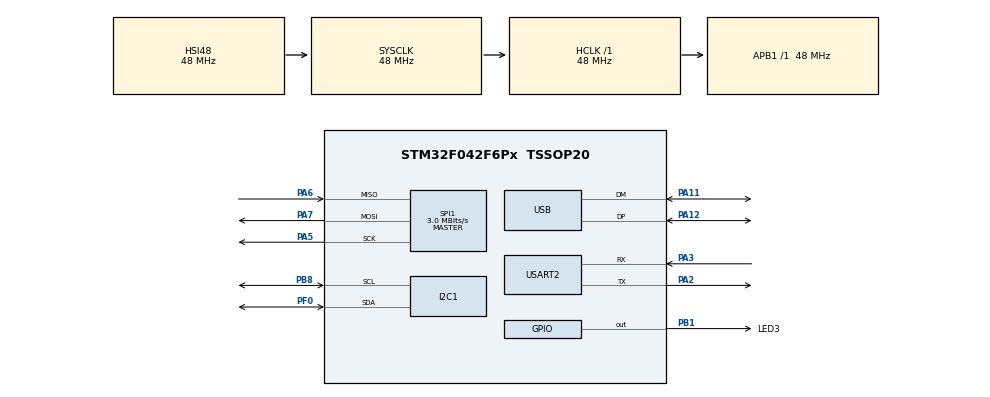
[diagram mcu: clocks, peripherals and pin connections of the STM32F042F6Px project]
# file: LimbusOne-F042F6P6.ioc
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Mcu.Family=STM32F0
Mcu.Name=STM32F042F6Px
Mcu.Package=TSSOP20
NVIC.USB_IRQn=true\:0\:0\:false\:false\:true\:false\:true\:true
PA11.Mode=Device
PA11.Signal=USB_DM
PA12.Mode=Device
PA12.Signal=USB_DP
PA13.Mode=Serial_Wire
PA13.Signal=SYS_SWDIO
PA14.Mode=Serial_Wire
PA14.Signal=SYS_SWCLK
PA2.Mode=Asynchronous
PA2.Signal=USART2_TX
PA3.Mode=Asynchronous
PA3.Signal=USART2_RX
PA5.Mode=Full_Duplex_Master
PA5.Signal=SPI1_SCK
PA6.Mode=Full_Duplex_Master
PA6.Signal=SPI1_MISO
PA7.Mode=Full_Duplex_Master
PA7.Signal=SPI1_MOSI
PB1.GPIO_Label=LED3
PB1.Signal=GPIO_Output
PB8.Mode=I2C
PB8.Signal=I2C1_SCL
PF0-OSC_IN.Mode=I2C
PF0-OSC_IN.Signal=I2C1_SDA
ProjectManager.HeapSize=0x000
ProjectManager.StackSize=0x100
ProjectManager.TargetToolchain=STM32CubeIDE
RCC.AHBFreq_Value=48000000
RCC.APB1Freq_Value=48000000
RCC.APB1TimFreq_Value=48000000
RCC.HCLKFreq_Value=48000000
RCC.SYSCLKFreq_VALUE=48000000
RCC.SYSCLKSource=RCC_SYSCLKSOURCE_HSI48
SPI1.BaudRatePrescaler=SPI_BAUDRATEPRESCALER_16
SPI1.CalculateBaudRate=3.0 MBits/s
SPI1.Direction=SPI_DIRECTION_2LINES
SPI1.Mode=SPI_MODE_MASTER
SPI1.VirtualType=VM_MASTER
USART2.VirtualMode-Asynchronous=VM_ASYNC
USB_DEVICE.CLASS_NAME_FS=CDC
USB_DEVICE.VirtualMode=Cdc
USB_DEVICE.VirtualModeFS=Cdc_FS
VP_SYS_VS_PINREMAP.Mode=PINREMAP
VP_USB_DEVICE_VS_USB_DEVICE_CDC_FS.Mode=CDC_FS
board=custom

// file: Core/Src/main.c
/* USER CODE BEGIN Header */
/**
  ******************************************************************************
  * @file           : main.c
  * @brief          : Main program body
  ******************************************************************************
  * @attention
  *
  * Copyright (c) 2024 STMicroelectronics.
  * All rights reserved.
  *
  * This software is licensed under terms that can be found in the LICENSE file
  * in the root directory of this software component.
  * If no LICENSE file comes with this software, it is provided AS-IS.
  *
  ******************************************************************************
  */
/* USER CODE END Header */
#include "main.h"
#include "i2c.h"
#include "spi.h"
#include "usart.h"
#include "usb_device.h"
#include "gpio.h"

void SystemClock_Config(void);

int main(void)
{

  /* MCU Configuration--------------------------------------------------------*/

  /* Reset of all peripherals, Initializes the Flash interface and the Systick. */
  HAL_Init();

  /* Configure the system clock */
  SystemClock_Config();

  /* Initialize all configured peripherals */
  MX_GPIO_Init();
  MX_I2C1_Init();
  MX_SPI1_Init();
  MX_USART2_UART_Init();
  MX_USB_DEVICE_Init();

  /* Infinite loop */
  while (1)
  {

    /* USER CODE BEGIN 3 */
	  for (uint8_t i = 0; i<255; i++)
	  {
		  ;
	  }
  }
  /* USER CODE END 3 */
}

void SystemClock_Config(void)
{
  RCC_OscInitTypeDef RCC_OscInitStruct = {0};
  RCC_ClkInitTypeDef RCC_ClkInitStruct = {0};
  RCC_PeriphCLKInitTypeDef PeriphClkInit = {0};

  /** Initializes the RCC Oscillators according to the specified parameters
  * in the RCC_OscInitTypeDef structure.
  */
  RCC_OscInitStruct.OscillatorType = RCC_OSCILLATORTYPE_HSI|RCC_OSCILLATORTYPE_HSI48;
  RCC_OscInitStruct.HSIState = RCC_HSI_ON;
  RCC_OscInitStruct.HSI48State = RCC_HSI48_ON;
  RCC_OscInitStruct.HSICalibrationValue = RCC_HSICALIBRATION_DEFAULT;
  RCC_OscInitStruct.PLL.PLLState = RCC_PLL_NONE;
  if (HAL_RCC_OscConfig(&RCC_OscInitStruct) != HAL_OK)
  {
    Error_Handler();
  }

  /** Initializes the CPU, AHB and APB buses clocks
  */
  RCC_ClkInitStruct.ClockType = RCC_CLOCKTYPE_HCLK|RCC_CLOCKTYPE_SYSCLK
                              |RCC_CLOCKTYPE_PCLK1;
  RCC_ClkInitStruct.SYSCLKSource = RCC_SYSCLKSOURCE_HSI48;
  RCC_ClkInitStruct.AHBCLKDivider = RCC_SYSCLK_DIV1;
  RCC_ClkInitStruct.APB1CLKDivider = RCC_HCLK_DIV1;

  if (HAL_RCC_ClockConfig(&RCC_ClkInitStruct, FLASH_LATENCY_1) != HAL_OK)
  {
    Error_Handler();
  }
  PeriphClkInit.PeriphClockSelection = RCC_PERIPHCLK_USB|RCC_PERIPHCLK_I2C1;
  PeriphClkInit.I2c1ClockSelection = RCC_I2C1CLKSOURCE_HSI;
  PeriphClkInit.UsbClockSelection = RCC_USBCLKSOURCE_HSI48;

  if (HAL_RCCEx_PeriphCLKConfig(&PeriphClkInit) != HAL_OK)
  {
    Error_Handler();
  }
}

void Error_Handler(void)
{
  __disable_irq();
  while (1)
  {
  }
}
